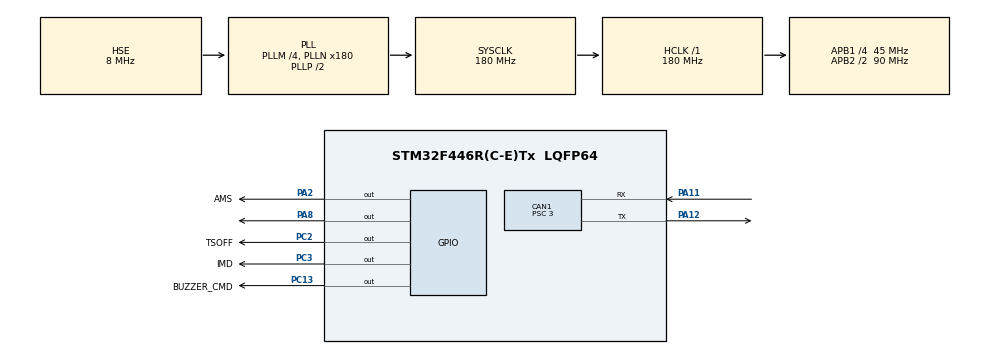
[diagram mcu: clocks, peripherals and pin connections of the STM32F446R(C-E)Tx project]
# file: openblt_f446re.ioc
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CAN1.ABOM=ENABLE
CAN1.BS1=CAN_BS1_12TQ
CAN1.BS2=CAN_BS2_2TQ
CAN1.CalculateBaudRate=1000000
CAN1.CalculateTimeBit=1000
CAN1.CalculateTimeQuantum=66.66666666666666
CAN1.NART=ENABLE
CAN1.Prescaler=3
Mcu.Family=STM32F4
Mcu.Name=STM32F446R(C-E)Tx
Mcu.Package=LQFP64
NVIC.PriorityGroup=NVIC_PRIORITYGROUP_4
PA11.Mode=CAN_Activate
PA11.Signal=CAN1_RX
PA12.Mode=CAN_Activate
PA12.Signal=CAN1_TX
PA13.Mode=Trace_Asynchronous_SW
PA13.Signal=SYS_JTMS-SWDIO
PA14.Mode=Trace_Asynchronous_SW
PA14.Signal=SYS_JTCK-SWCLK
PA2.GPIO_Label=AMS
PA2.PinState=GPIO_PIN_SET
PA2.Signal=GPIO_Output
PA8.Signal=GPIO_Output
PB3.Mode=Trace_Asynchronous_SW
PB3.Signal=SYS_JTDO-SWO
PC13.GPIO_Label=BUZZER_CMD
PC13.Signal=GPIO_Output
PC2.GPIO_Label=TSOFF
PC2.Signal=GPIO_Output
PC3.GPIO_Label=IMD
PC3.PinState=GPIO_PIN_SET
PC3.Signal=GPIO_Output
PH0-OSC_IN.Mode=HSE-External-Oscillator
PH0-OSC_IN.Signal=RCC_OSC_IN
PH1-OSC_OUT.Mode=HSE-External-Oscillator
PH1-OSC_OUT.Signal=RCC_OSC_OUT
ProjectManager.HeapSize=0x200
ProjectManager.StackSize=0x400
ProjectManager.TargetToolchain=Makefile
RCC.AHBFreq_Value=180000000
RCC.APB1CLKDivider=RCC_HCLK_DIV4
RCC.APB1Freq_Value=45000000
RCC.APB1TimFreq_Value=90000000
RCC.APB2CLKDivider=RCC_HCLK_DIV2
RCC.APB2Freq_Value=90000000
RCC.APB2TimFreq_Value=180000000
RCC.CortexFreq_Value=180000000
RCC.HCLKFreq_Value=180000000
RCC.HSE_VALUE=8000000
RCC.PLLM=4
RCC.PLLN=180
RCC.PLLSourceVirtual=RCC_PLLSOURCE_HSE
RCC.SYSCLKFreq_VALUE=180000000
RCC.SYSCLKSource=RCC_SYSCLKSOURCE_PLLCLK
RCC.USBFreq_Value=180000000
RCC.VCOOutputFreq_Value=360000000
board=custom

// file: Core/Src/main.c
/* USER CODE BEGIN Header */
/**
  ******************************************************************************
  * @file           : main.c
  * @brief          : Main program body
  ******************************************************************************
  * @attention
  *
  * Copyright (c) 2022 STMicroelectronics.
  * All rights reserved.
  *
  * This software is licensed under terms that can be found in the LICENSE file
  * in the root directory of this software component.
  * If no LICENSE file comes with this software, it is provided AS-IS.
  *
  ******************************************************************************
  */
/* USER CODE END Header */
#include "main.h"

/* USER CODE BEGIN Includes */
#include "boot.h"
/* USER CODE END Includes */

CAN_HandleTypeDef hcan1;

void SystemClock_Config(void);
static void MX_GPIO_Init(void);
static void MX_CAN1_Init(void);

int main(void)
{

  /* MCU Configuration--------------------------------------------------------*/

  /* Reset of all peripherals, Initializes the Flash interface and the Systick. */
  HAL_Init();

  /* Configure the system clock */
  SystemClock_Config();

  /* Initialize all configured peripherals */
  MX_GPIO_Init();
  MX_CAN1_Init();
  /* USER CODE BEGIN 2 */
  BootInit();

  HAL_GPIO_WritePin(BUZZER_CMD_GPIO_Port, BUZZER_CMD_Pin, GPIO_PIN_RESET);

  /* USER CODE END 2 */

  /* Infinite loop */
  /* USER CODE BEGIN WHILE */
  while (1)
  {
    BootTask();
    /* USER CODE END WHILE */

  }
}

void SystemClock_Config(void)
{
  RCC_OscInitTypeDef RCC_OscInitStruct = {0};
  RCC_ClkInitTypeDef RCC_ClkInitStruct = {0};

  /** Configure the main internal regulator output voltage
  */
  __HAL_RCC_PWR_CLK_ENABLE();
  __HAL_PWR_VOLTAGESCALING_CONFIG(PWR_REGULATOR_VOLTAGE_SCALE1);

  /** Initializes the RCC Oscillators according to the specified parameters
  * in the RCC_OscInitTypeDef structure.
  */
  RCC_OscInitStruct.OscillatorType = RCC_OSCILLATORTYPE_HSE;
  RCC_OscInitStruct.HSEState = RCC_HSE_ON;
  RCC_OscInitStruct.PLL.PLLState = RCC_PLL_ON;
  RCC_OscInitStruct.PLL.PLLSource = RCC_PLLSOURCE_HSE;
  RCC_OscInitStruct.PLL.PLLM = 4;
  RCC_OscInitStruct.PLL.PLLN = 180;
  RCC_OscInitStruct.PLL.PLLP = RCC_PLLP_DIV2;
  RCC_OscInitStruct.PLL.PLLQ = 2;
  RCC_OscInitStruct.PLL.PLLR = 2;
  if (HAL_RCC_OscConfig(&RCC_OscInitStruct) != HAL_OK)
  {
    Error_Handler();
  }

  /** Activate the Over-Drive mode
  */
  if (HAL_PWREx_EnableOverDrive() != HAL_OK)
  {
    Error_Handler();
  }

  /** Initializes the CPU, AHB and APB buses clocks
  */
  RCC_ClkInitStruct.ClockType = RCC_CLOCKTYPE_HCLK|RCC_CLOCKTYPE_SYSCLK
                              |RCC_CLOCKTYPE_PCLK1|RCC_CLOCKTYPE_PCLK2;
  RCC_ClkInitStruct.SYSCLKSource = RCC_SYSCLKSOURCE_PLLCLK;
  RCC_ClkInitStruct.AHBCLKDivider = RCC_SYSCLK_DIV1;
  RCC_ClkInitStruct.APB1CLKDivider = RCC_HCLK_DIV4;
  RCC_ClkInitStruct.APB2CLKDivider = RCC_HCLK_DIV2;

  if (HAL_RCC_ClockConfig(&RCC_ClkInitStruct, FLASH_LATENCY_5) != HAL_OK)
  {
    Error_Handler();
  }
}

static void MX_CAN1_Init(void)
{

  hcan1.Instance = CAN1;
  hcan1.Init.Prescaler = 3;
  hcan1.Init.Mode = CAN_MODE_NORMAL;
  hcan1.Init.SyncJumpWidth = CAN_SJW_1TQ;
  hcan1.Init.TimeSeg1 = CAN_BS1_12TQ;
  hcan1.Init.TimeSeg2 = CAN_BS2_2TQ;
  hcan1.Init.TimeTriggeredMode = DISABLE;
  hcan1.Init.AutoBusOff = ENABLE;
  hcan1.Init.AutoWakeUp = DISABLE;
  hcan1.Init.AutoRetransmission = ENABLE;
  hcan1.Init.ReceiveFifoLocked = DISABLE;
  hcan1.Init.TransmitFifoPriority = DISABLE;
  if (HAL_CAN_Init(&hcan1) != HAL_OK)
  {
    Error_Handler();
  }

}

static void MX_GPIO_Init(void)
{
  GPIO_InitTypeDef GPIO_InitStruct = {0};

  /* GPIO Ports Clock Enable */
  __HAL_RCC_GPIOC_CLK_ENABLE();
  __HAL_RCC_GPIOH_CLK_ENABLE();
  __HAL_RCC_GPIOA_CLK_ENABLE();
  __HAL_RCC_GPIOB_CLK_ENABLE();
  __HAL_RCC_GPIOD_CLK_ENABLE();

  /*Configure GPIO pin Output Level */
  HAL_GPIO_WritePin(GPIOC, BUZZER_CMD_Pin|TSOFF_Pin, GPIO_PIN_RESET);

  /*Configure GPIO pin Output Level */
  HAL_GPIO_WritePin(IMD_GPIO_Port, IMD_Pin, GPIO_PIN_SET);

  /*Configure GPIO pin Output Level */
  HAL_GPIO_WritePin(AMS_GPIO_Port, AMS_Pin, GPIO_PIN_SET);

  /*Configure GPIO pin Output Level */
  HAL_GPIO_WritePin(GPIOA, GPIO_PIN_8, GPIO_PIN_RESET);

  /*Configure GPIO pins : BUZZER_CMD_Pin TSOFF_Pin IMD_Pin */
  GPIO_InitStruct.Pin = BUZZER_CMD_Pin|TSOFF_Pin|IMD_Pin;
  GPIO_InitStruct.Mode = GPIO_MODE_OUTPUT_PP;
  GPIO_InitStruct.Pull = GPIO_NOPULL;
  GPIO_InitStruct.Speed = GPIO_SPEED_FREQ_LOW;
  HAL_GPIO_Init(GPIOC, &GPIO_InitStruct);

  /*Configure GPIO pins : PC14 PC15 PC0 PC1
                           PC4 PC5 PC6 PC7
                           PC8 PC9 PC10 PC11
                           PC12 */
  GPIO_InitStruct.Pin = GPIO_PIN_14|GPIO_PIN_15|GPIO_PIN_0|GPIO_PIN_1
                          |GPIO_PIN_4|GPIO_PIN_5|GPIO_PIN_6|GPIO_PIN_7
                          |GPIO_PIN_8|GPIO_PIN_9|GPIO_PIN_10|GPIO_PIN_11
                          |GPIO_PIN_12;
  GPIO_InitStruct.Mode = GPIO_MODE_ANALOG;
  GPIO_InitStruct.Pull = GPIO_NOPULL;
  HAL_GPIO_Init(GPIOC, &GPIO_InitStruct);

  /*Configure GPIO pins : PA0 PA1 PA3 PA4
                           PA5 PA6 PA7 PA9
                           PA10 PA15 */
  GPIO_InitStruct.Pin = GPIO_PIN_0|GPIO_PIN_1|GPIO_PIN_3|GPIO_PIN_4
                          |GPIO_PIN_5|GPIO_PIN_6|GPIO_PIN_7|GPIO_PIN_9
                          |GPIO_PIN_10|GPIO_PIN_15;
  GPIO_InitStruct.Mode = GPIO_MODE_ANALOG;
  GPIO_InitStruct.Pull = GPIO_NOPULL;
  HAL_GPIO_Init(GPIOA, &GPIO_InitStruct);

  /*Configure GPIO pins : AMS_Pin PA8 */
  GPIO_InitStruct.Pin = AMS_Pin|GPIO_PIN_8;
  GPIO_InitStruct.Mode = GPIO_MODE_OUTPUT_PP;
  GPIO_InitStruct.Pull = GPIO_NOPULL;
  GPIO_InitStruct.Speed = GPIO_SPEED_FREQ_LOW;
  HAL_GPIO_Init(GPIOA, &GPIO_InitStruct);

  /*Configure GPIO pins : PB0 PB1 PB2 PB10
                           PB12 PB13 PB14 PB15
                           PB4 PB5 PB6 PB7
                           PB8 PB9 */
  GPIO_InitStruct.Pin = GPIO_PIN_0|GPIO_PIN_1|GPIO_PIN_2|GPIO_PIN_10
                          |GPIO_PIN_12|GPIO_PIN_13|GPIO_PIN_14|GPIO_PIN_15
                          |GPIO_PIN_4|GPIO_PIN_5|GPIO_PIN_6|GPIO_PIN_7
                          |GPIO_PIN_8|GPIO_PIN_9;
  GPIO_InitStruct.Mode = GPIO_MODE_ANALOG;
  GPIO_InitStruct.Pull = GPIO_NOPULL;
  HAL_GPIO_Init(GPIOB, &GPIO_InitStruct);

  /*Configure GPIO pin : PD2 */
  GPIO_InitStruct.Pin = GPIO_PIN_2;
  GPIO_InitStruct.Mode = GPIO_MODE_ANALOG;
  GPIO_InitStruct.Pull = GPIO_NOPULL;
  HAL_GPIO_Init(GPIOD, &GPIO_InitStruct);

}

void Error_Handler(void)
{
  __disable_irq();
  while (1)
  {
  }
}
